# M46B register map
File version: 2.0.2.2
Registers are 32-bit, read-write, reset 0x0 unless marked. A register's access mark holds for its fields unless they carry their own. Offsets are from the block's base; [hi:lo] are bit positions; {n}, {i} and the like mark numbered series.

## RTC — Real Time Clock (RTC)
Base 0x400CC000
0x00 SECR 8-bit (reset mask 0x80) — RTC Sec setting register
  [6:0] SE
0x01 MINR 8-bit (reset mask 0x80) — RTC Min settging register
  [6:0] MI
0x02 HOURR 8-bit (reset mask 0xC0) — RTC Hour setting register
  [5:0] HO
0x04 DAYR 8-bit (reset mask 0xF8) — RTC Day setting register
  [2:0] WE
0x05 DATER 8-bit (reset mask 0xC0) — RTC Date setting register
  [5:0] DA
0x06 MONTHR 8-bit (reset mask 0xE0) — RTC Month settging register PAGE0
  [4:0] MO
0x07 YEARR_A 8-bit reset not defined — RTC Year setting register PAGE0
  [7:0] YE
0x07 YEARR_B 8-bit (reset mask 0xFC) (RTC_YEARR view) — RTC Leap year register PAGE1
  [1:0] LEAP
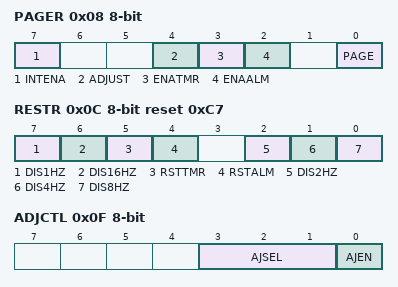
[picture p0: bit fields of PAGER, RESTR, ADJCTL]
0x08 PAGER 8-bit (reset mask 0xF3) — RTC Page register
  [7] INTENA, [4] ADJUST, [3] ENATMR, [2] ENAALM, [0] PAGE
0x0C RESTR 8-bit reset 0xC7 — RTC Reset register
  [7] DIS1HZ, [6] DIS16HZ, [5] RSTTMR, [4] RSTALM, [2] DIS2HZ, [1] DIS4HZ, [0] DIS8HZ
0x0E PROTECT 8-bit reset 0xC1 — RTC protect register
0x0F ADJCTL 8-bit (reset mask 0xF0) — RTC clock adjust control register
  [3:1] AJSEL, [0] AJEN
0x10 ADJDAT 16-bit (reset mask 0xFE00) — RTC clock adjust data register
  [8:0] ADJDAT

## SC0 — Serial Channel (SC)
Base 0x400E1000
Same registers: SC1 0x400E1100, SC2 0x400E1200, SC3 0x400E1300
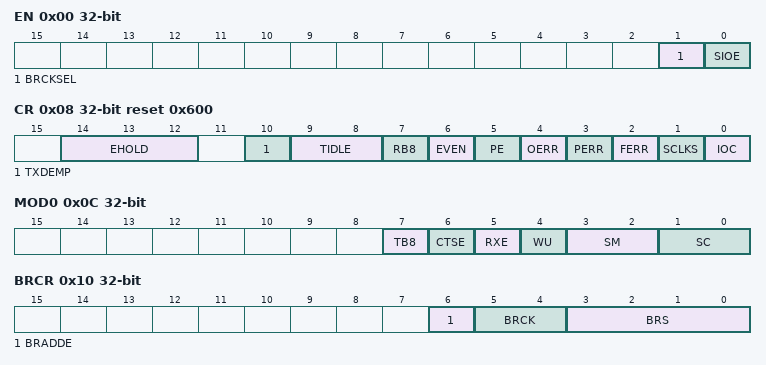
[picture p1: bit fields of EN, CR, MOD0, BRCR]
0x00 EN — SC Enable Register
  [1] BRCKSEL, [0] SIOE
0x04 BUF — SC Buffer Register
  [7:0] TB_RB
0x08 CR reset 0x600 — SC Control Register
  [14:12] EHOLD, [10] TXDEMP, [9:8] TIDLE, [7] RB8 ro, [6] EVEN, [5] PE, [4] OERR ro, [3] PERR ro, [2] FERR ro, [1] SCLKS, [0] IOC
0x0C MOD0 — SC Mode Control Register 0
  [7] TB8, [6] CTSE, [5] RXE, [4] WU, [3:2] SM, [1:0] SC
0x10 BRCR — SC Baud Rate Generator Control Register
  [6] BRADDE, [5:4] BRCK, [3:0] BRS
0x14 BRADD — SC Baud Rate Generator Control Register 2
  [3:0] BRK
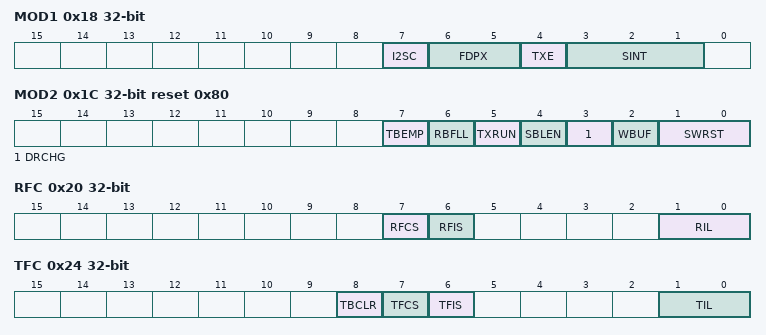
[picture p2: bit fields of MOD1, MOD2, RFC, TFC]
0x18 MOD1 — SC Mode Control Register 1
  [7] I2SC, [6:5] FDPX, [4] TXE, [3:1] SINT
0x1C MOD2 reset 0x80 — SC Mode Control Register 2
  [7] TBEMP ro, [6] RBFLL ro, [5] TXRUN ro, [4] SBLEN, [3] DRCHG, [2] WBUF, [1:0] SWRST
0x20 RFC — SC RX FIFO Configuration Register
  [7] RFCS wo, [6] RFIS, [1:0] RIL
0x24 TFC — SC TX FIFO Configuration Register
  [8] TBCLR wo, [7] TFCS wo, [6] TFIS, [1:0] TIL
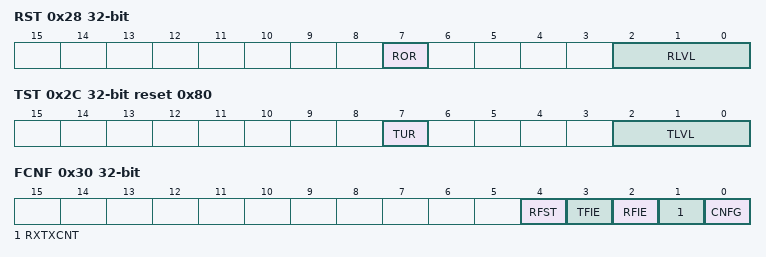
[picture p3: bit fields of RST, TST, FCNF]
0x28 RST ro — SC RX FIFO Status Register
  [7] ROR, [2:0] RLVL
0x2C TST ro reset 0x80 — SC TX FIFO Status Register
  [7] TUR, [2:0] TLVL
0x30 FCNF — SC FIFO Configuration Register
  [4] RFST, [3] TFIE, [2] RFIE, [1] RXTXCNT, [0] CNFG

## WD — Watchdog Timer (WD)
Base 0x400F2000
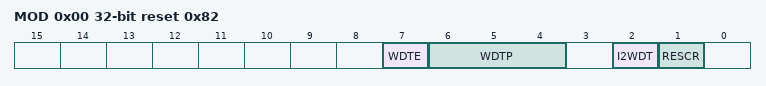
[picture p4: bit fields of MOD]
0x00 MOD reset 0x82 — WD Mode Register
  [7] WDTE, [6:4] WDTP, [2] I2WDT, [1] RESCR
0x04 CR wo (reset mask 0xFFFFFF00) — WD Control Register
  [7:0] WDCR

## CG — Clock Generator (CG)
Base 0x400F3000
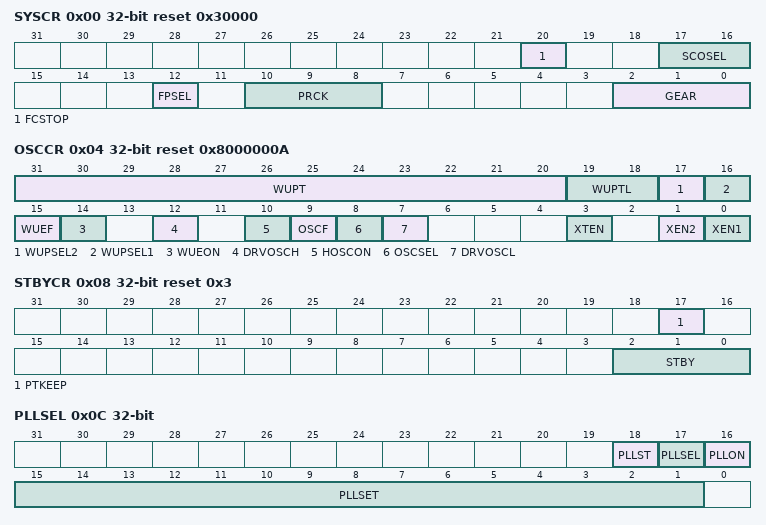
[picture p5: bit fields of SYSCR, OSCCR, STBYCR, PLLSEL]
0x00 SYSCR reset 0x30000 — System Control Register
  [20] FCSTOP, [17:16] SCOSEL, [12] FPSEL, [10:8] PRCK, [2:0] GEAR
0x04 OSCCR reset 0x8000000A — Oscillation Control Register
  [31:20] WUPT, [19:18] WUPTL, [17] WUPSEL2, [16] WUPSEL1, [15] WUEF ro, [14] WUEON wo, [12] DRVOSCH, [10] HOSCON, [9] OSCF ro, [8] OSCSEL, [7] DRVOSCL, [3] XTEN, [1] XEN2, [0] XEN1
0x08 STBYCR reset 0x3 — Standby Control Register
  [17] PTKEEP, [2:0] STBY
0x0C PLLSEL — PLL Selection Register
  [18] PLLST ro, [17] PLLSEL, [16] PLLON, [15:1] PLLSET
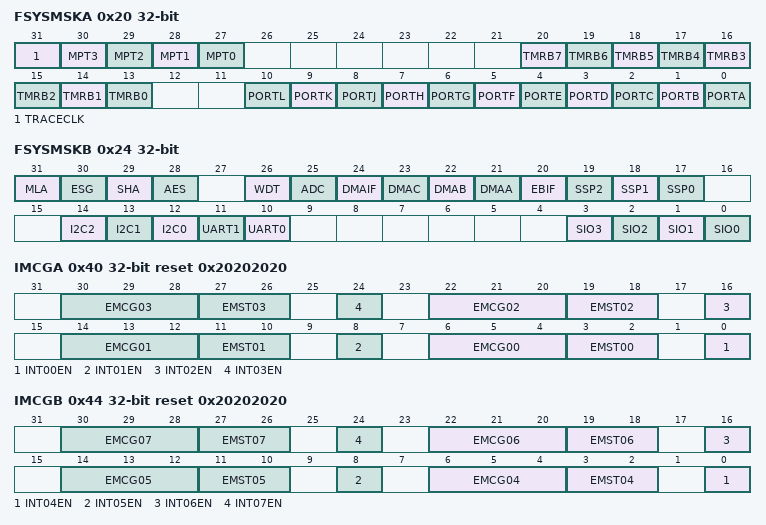
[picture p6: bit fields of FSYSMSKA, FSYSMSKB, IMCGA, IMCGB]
0x20 FSYSMSKA — fclk Supply Stop Register A
  [31] TRACECLK, [n+27] MPT{n} (n=0..3), [n+13] TMRB{n} (n=0..7), [10] PORTL, [9] PORTK, [8] PORTJ, [7] PORTH, [6] PORTG, [5] PORTF, [4] PORTE, [3] PORTD, [2] PORTC, [1] PORTB, [0] PORTA
0x24 FSYSMSKB — fclk Supply Stop Register B
  [31] MLA ro, [30] ESG, [29] SHA, [28] AES, [26] WDT, [25] ADC, [24] DMAIF, [23] DMAC, [22] DMAB, [21] DMAA, [20] EBIF, [19] SSP2, [18] SSP1, [17] SSP0, [14] I2C2, [13] I2C1, [12] I2C0, [11] UART1, [10] UART0, [n] SIO{n} (n=0..3)
0x3C PROTECT reset 0xC1
  [7:0] CGPROTECT
0x40 IMCGA reset 0x20202020 — CG Interrupt Mode Control Register A
  [8n+6:8n+4] EMCG{n:02} (n=0..3), [8n+3:8n+2] EMST{n:02} ro (n=0..3), [8n] INT{n:02}EN (n=0..3)
0x44 IMCGB reset 0x20202020 — CG Interrupt Mode Control Register B
  [8n-26:8n-28] EMCG{n:02} (n=4..7), [8n-29:8n-30] EMST{n:02} ro (n=4..7), [8n-32] INT{n:02}EN (n=4..7)
0x60 ICRCG wo — CG Interrupt Request Clear Register
  [4:0] ICRCG
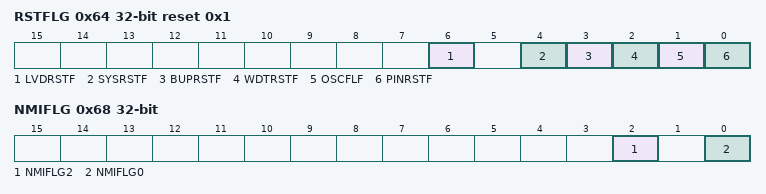
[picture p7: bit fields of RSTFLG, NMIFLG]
0x64 RSTFLG reset 0x1 (reset mask 0xFFFFFFFD) — Reset Flag Register
  [6] LVDRSTF, [4] SYSRSTF, [3] BUPRSTF, [2] WDTRSTF, [1] OSCFLF ro, [0] PINRSTF
0x68 NMIFLG ro — NMI Flag Register
  [2] NMIFLG2, [0] NMIFLG0

## LVD — Low voltage detecter
Base 0x400F4000
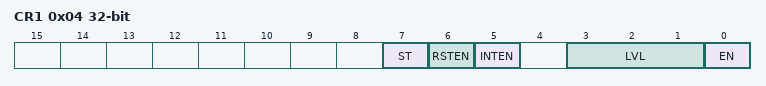
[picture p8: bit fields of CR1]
0x04 CR1 — LVD detection control register 1
  [7] ST ro, [6] RSTEN, [5] INTEN, [3:1] LVL, [0] EN

## FC — Flash Control (FC)
Base 0x5DFF0000
0x10 SECBIT reset 0x1 — Security Bit Register
  [0] SECBIT
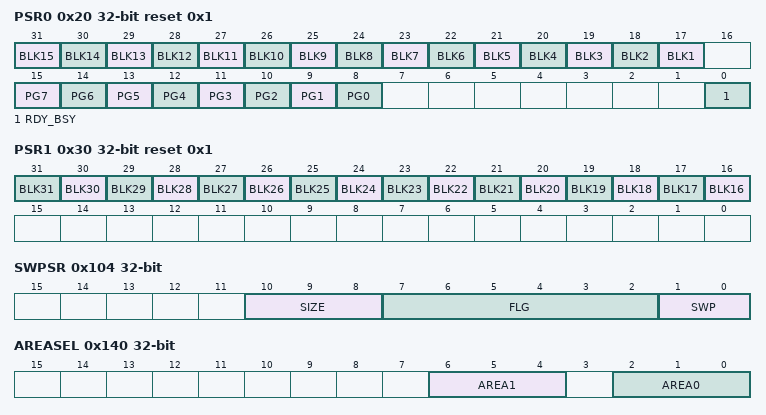
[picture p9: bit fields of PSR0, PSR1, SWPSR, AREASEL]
0x20 PSR0 ro reset 0x1 (reset mask 0xFF) — Protect Status Register 0
  [n+16] BLK{n} (n=1..15), [n+8] PG{n} (n=0..7), [0] RDY_BSY
0x30 PSR1 ro reset 0x1 (reset mask 0xFFFF) — Protect Status Register 1
  [n] BLK{n} (n=16..31)
0x100 SR ro — Status Register
  [24] WEABORT
0x104 SWPSR ro — Swap Status Register
  [10:8] SIZE, [7:2] FLG, [1:0] SWP
0x140 AREASEL — Area Selection Register
  [6:4] AREA1, [2:0] AREA0
0x148 CR — Control Register
  [2:0] WEABORT
0x14C STSCLR — Status Clear Register
  [2:0] WEABORT
0x150 WCLKCR — WCLK Configuration Register
  [4:0] DIV
0x154 PROGCR — Program Counter Configuration Register
  [1:0] CNT
0x158 ERASECR reset 0x6 — Erase Counter Configuration Register
  [3:0] CNT
